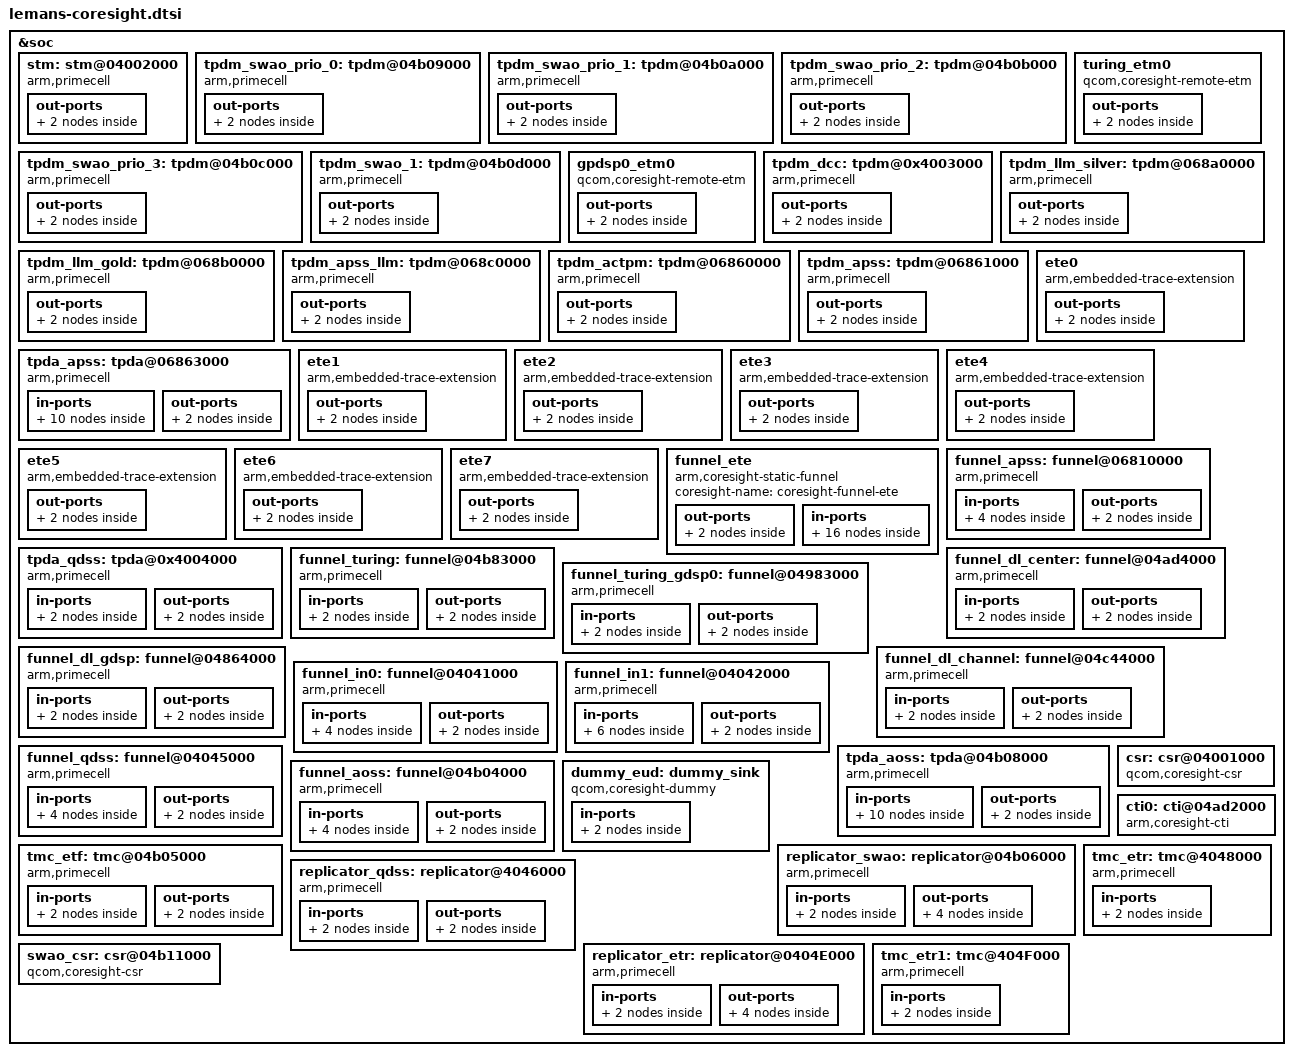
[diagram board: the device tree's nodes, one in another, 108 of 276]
&soc {
	stm: stm@04002000 {
		compatible = "arm,primecell";
		arm,primecell-periphid = <0x000bb962>;
		reg = <0x04002000 0x1000>,
			<0x16280000 0x180000>;
		reg-names = "stm-base", "stm-stimulus-base";

		atid = <16>;
		coresight-name = "coresight-stm";

		clocks = <&aoss_qmp QDSS_CLK>;
		clock-names = "apb_pclk";

		out-ports {
			port {
				stm_out_funnel_in0: endpoint {
					remote-endpoint =
					<&funnel_in0_in_stm>;
				};
			};
		};
	};

	tpdm_swao_prio_0: tpdm@04b09000 {
		compatible = "arm,primecell";
		arm,primecell-periphid = <0x000bb968>;
		reg = <0x04b09000 0x1000>;
		reg-names = "tpdm-base";

		atid = <71>;
		coresight-name = "coresight-tpdm-swao-prio-0";

		clocks = <&aoss_qmp>;
		clock-names = "apb_pclk";

		out-ports {
			port {
				tpdm_swao_prio_0_out_tpda_aoss_0: endpoint {
					remote-endpoint =
					<&tpda_aoss_0_in_tpdm_swao_prio_0>;
				};
			};
		};
	};

	tpdm_swao_prio_1: tpdm@04b0a000 {
		compatible = "arm,primecell";
		arm,primecell-periphid = <0x000bb968>;
		reg = <0x04b0a000 0x1000>;
		reg-names = "tpdm-base";

		atid = <71>;
		coresight-name = "coresight-tpdm-swao-prio-1";

		clocks = <&aoss_qmp>;
		clock-names = "apb_pclk";

		out-ports {
			port {
				tpdm_swao_prio_1_out_tpda_aoss_1: endpoint {
					remote-endpoint =
					<&tpda_aoss_1_in_tpdm_swao_prio_1>;
				};
			};
		};
	};

	tpdm_swao_prio_2: tpdm@04b0b000 {
		compatible = "arm,primecell";
		arm,primecell-periphid = <0x000bb968>;
		reg = <0x04b0b000 0x1000>;
		reg-names = "tpdm-base";

		atid = <71>;
		coresight-name = "coresight-tpdm-swao-prio-2";

		clocks = <&aoss_qmp>;
		clock-names = "apb_pclk";

		out-ports {
			port {
				tpdm_swao_prio_2_out_tpda_aoss_2: endpoint {
					remote-endpoint =
					 <&tpda_aoss_2_in_tpdm_swao_prio_2>;
				};
			};
		};
	};

	tpdm_swao_prio_3: tpdm@04b0c000 {
		compatible = "arm,primecell";
		arm,primecell-periphid = <0x000bb968>;
		reg = <0x04b0c000 0x1000>;
		reg-names = "tpdm-base";

		atid = <71>;
		coresight-name = "coresight-tpdm-swao-prio-3";

		clocks = <&aoss_qmp>;
		clock-names = "apb_pclk";

		out-ports {
			port {
				tpdm_swao_prio_3_out_tpda_aoss_3: endpoint {
					remote-endpoint =
					 <&tpda_aoss_3_in_tpdm_swao_prio_3>;
				};
			};
		};
	};

	tpdm_swao_1: tpdm@04b0d000 {
		compatible = "arm,primecell";
		arm,primecell-periphid = <0x000bb968>;
		reg = <0x04b0d000 0x1000>;
		reg-names = "tpdm-base";

		atid = <71>;
		coresight-name = "coresight-tpdm-swao-1";

		clocks = <&aoss_qmp>;
		clock-names = "apb_pclk";

		out-ports {
			port {
				tpdm_swao_out_tpda_aoss_4: endpoint {
					remote-endpoint =
					<&tpda_aoss_4_in_tpdm_swao>;
				};
			};
		};
	};

	turing_etm0: turing_etm0 {
		compatible = "qcom,coresight-remote-etm";
		coresight-name = "coresight-turing-etm0";
		qcom,inst-id = <13>;
		atid = <38 39>;

		out-ports {
			port {
				turing_etm0_out_funnel_turing_4: endpoint {
					remote-endpoint =
					<&funnel_turing_4_in_turing_etm0>;
				};
			};
		};
	};

	gpdsp0_etm0: gpdsp0_etm0 {
		compatible = "qcom,coresight-remote-etm";

		coresight-name = "coresight-gpdsp-etm0";
		qcom,inst-id = <13>;

		atid = <51 52>;

		out-ports {
			port {
				gpdsp0_etm0_out_funnel_turing_gdsp0_2: endpoint {
					remote-endpoint =
					<&funnel_turing_gdsp0_2_in_gpdsp0_etm0>;
				};
			};
		};
	};

	tpdm_dcc: tpdm@0x4003000 {
		compatible = "arm,primecell";
		arm,primecell-periphid = <0x000bb968>;
		reg = <0x4003000 0x1000>;
		reg-names = "tpdm-base";

		atid = <65>;
		coresight-name = "coresight-tpdm-dcc";

		clocks = <&aoss_qmp>;
		clock-names = "apb_pclk";
		qcom,hw-enable-check;

		out-ports {
			port {
				tpdm_dcc_out_tpda_qdss_0: endpoint {
					remote-endpoint =
					<&tpda_qdss_0_in_tpdm_dcc>;
				};
			};
		};
	};

	tpdm_llm_silver: tpdm@068a0000 {
		compatible = "arm,primecell";
		arm,primecell-periphid = <0x000bb968>;
		reg = <0x068a0000 0x1000>;
		reg-names = "tpdm-base";

		atid = <66>;
		coresight-name = "coresight-tpdm-llm-silver";

		clocks = <&aoss_qmp QDSS_CLK>;
		clock-names = "apb_pclk";

		out-ports {
			port {
				tpdm_llm_silver_out_tpda_apss_0: endpoint {
					remote-endpoint =
					<&tpda_apss_0_in_tpdm_llm_silver>;
				};
			};
		};
	};

	tpdm_llm_gold: tpdm@068b0000 {
		compatible = "arm,primecell";
		arm,primecell-periphid = <0x000bb968>;
		reg = <0x068b0000 0x1000>;
		reg-names = "tpdm-base";

		atid = <66>;
		coresight-name = "coresight-tpdm-llm-gold";

		clocks = <&aoss_qmp QDSS_CLK>;
		clock-names = "apb_pclk";

		out-ports {
			port {
				tpdm_llm_gold_out_tpda_apss_1: endpoint {
					remote-endpoint =
					<&tpda_apss_1_in_tpdm_llm_gold>;
				};
			};
		};
	};

	tpdm_apss_llm: tpdm@068c0000 {
		compatible = "arm,primecell";
		arm,primecell-periphid = <0x000bb968>;
		reg = <0x068c0000 0x1000>;
		reg-names = "tpdm-base";

		atid = <66>;
		coresight-name = "coresight-tpdm-apss-llm";

		clocks = <&aoss_qmp QDSS_CLK>;
		clock-names = "apb_pclk";

		out-ports {
			port {
				tpdm_apss_llm_out_tpda_apss_2: endpoint {
					remote-endpoint =
					<&tpda_apss_2_in_tpdm_apss_llm>;
				};
			};
		};
	};

	tpdm_actpm: tpdm@06860000 {
		compatible = "arm,primecell";
		arm,primecell-periphid = <0x000bb968>;
		reg = <0x06860000 0x1000>;
		reg-names = "tpdm-base";

		atid = <66>;
		coresight-name = "coresight-tpdm-actpm";

		clocks = <&aoss_qmp QDSS_CLK>;
		clock-names = "apb_pclk";

		out-ports {
			port {
				tpdm_apss0_out_tpda_apss_3: endpoint {
					remote-endpoint =
					<&tpda_apss_3_in_tpdm_apss0>;
				};
			};
		};
	};

	tpdm_apss: tpdm@06861000 {
		compatible = "arm,primecell";
		arm,primecell-periphid = <0x000bb968>;
		reg = <0x06861000 0x1000>;
		reg-names = "tpdm-base";

		atid = <66>;
		coresight-name = "coresight-tpdm-apss";

		clocks = <&aoss_qmp QDSS_CLK>;
		clock-names = "apb_pclk";

		out-ports {
			port {
				tpdm_apps1_out_tpda_apss_4: endpoint {
					remote-endpoint =
					<&tpda_apss_4_in_tpdm_apps1>;
				};
			};
		};
	};

	tpda_apss: tpda@06863000 {
		compatible = "arm,primecell";
		arm,primecell-periphid = <0x000bb969>;

		reg = <0x06863000 0x1000>;
		reg-names = "tpda-base";

		qcom,tpda-atid = <66>;

		qcom,dsb-elem-size = <2 32>,
					<4 32>;
		qcom,cmb-elem-size = <0 32>,
				     <1 32>,
				     <3 64>;

		coresight-name = "coresight-tpda-apss";

		clocks = <&aoss_qmp QDSS_CLK>;
		clock-names = "apb_pclk";

		in-ports {

			#address-cells = <1>;
			#size-cells = <0>;

			port@0 {
				reg = <0>;
				tpda_apss_0_in_tpdm_llm_silver: endpoint {
					remote-endpoint =
					<&tpdm_llm_silver_out_tpda_apss_0>;
				};
			};

			port@1 {
				reg = <1>;
				tpda_apss_1_in_tpdm_llm_gold: endpoint {
					remote-endpoint =
					<&tpdm_llm_gold_out_tpda_apss_1>;
				};
			};

			port@3 {
				reg = <3>;
				tpda_apss_3_in_tpdm_apss0: endpoint {
					remote-endpoint =
					<&tpdm_apss0_out_tpda_apss_3>;
				};
			};

			port@2 {
				reg = <2>;
				tpda_apss_2_in_tpdm_apss_llm: endpoint {
					remote-endpoint =
					<&tpdm_apss_llm_out_tpda_apss_2>;
				};
			};

			port@4 {
				reg = <4>;
				tpda_apss_4_in_tpdm_apps1: endpoint {
					remote-endpoint =
					<&tpdm_apps1_out_tpda_apss_4>;
				};
			};

		};

		out-ports {

			port {
				tpda_apss_out_funnel_apss: endpoint {
					remote-endpoint =
					<&funnel_apss_in_tpda_apss>;
				};
			};

		};
	};

	ete0 {
		compatible = "arm,embedded-trace-extension";
		cpu = <&CPU0>;

		coresight-name = "coresight-ete0";
		qcom,skip-power-up;
		atid = <1>;
		out-ports {
			port {
				ete0_out_funnel_ete: endpoint {
				remote-endpoint = <&funnel_ete_in_ete0>;
				};
			};
		};
	};

	ete1 {
		compatible = "arm,embedded-trace-extension";
		cpu = <&CPU1>;

		coresight-name = "coresight-ete1";
		qcom,skip-power-up;
		atid = <2>;
		out-ports {
			port {
				ete1_out_funnel_ete: endpoint {
				remote-endpoint = <&funnel_ete_in_ete1>;
				};
			};
		};
	};

	ete2 {
		compatible = "arm,embedded-trace-extension";
		cpu = <&CPU2>;

		coresight-name = "coresight-ete2";
		qcom,skip-power-up;
		atid = <3>;
		out-ports {
			port {
				ete2_out_funnel_ete: endpoint {
				remote-endpoint = <&funnel_ete_in_ete2>;
				};
			};
		};
	};

	ete3 {
		compatible = "arm,embedded-trace-extension";
		cpu = <&CPU3>;

		coresight-name = "coresight-ete3";
		qcom,skip-power-up;
		atid = <4>;
		out-ports {
			port {
				ete3_out_funnel_ete: endpoint {
				remote-endpoint = <&funnel_ete_in_ete3>;
				};
			};
		};
	};

	ete4 {
		compatible = "arm,embedded-trace-extension";
		cpu = <&CPU4>;

		coresight-name = "coresight-ete4";
		qcom,skip-power-up;
		atid = <5>;
		out-ports {
			port {
				ete4_out_funnel_ete: endpoint {
				remote-endpoint = <&funnel_ete_in_ete4>;
				};
			};
		};
	};

	ete5 {
		compatible = "arm,embedded-trace-extension";
		cpu = <&CPU5>;

		coresight-name = "coresight-ete5";
		qcom,skip-power-up;
		atid = <6>;
		out-ports {
			port {
				ete5_out_funnel_ete: endpoint {
				remote-endpoint = <&funnel_ete_in_ete5>;
				};
			};
		};
	};

	ete6 {
		compatible = "arm,embedded-trace-extension";
		cpu = <&CPU6>;

		coresight-name = "coresight-ete6";
		qcom,skip-power-up;
		atid = <7>;
		out-ports {
			port {
				ete6_out_funnel_ete: endpoint {
				remote-endpoint = <&funnel_ete_in_ete6>;
				};
			};
		};
	};

	ete7 {
		compatible = "arm,embedded-trace-extension";
		cpu = <&CPU7>;

		coresight-name = "coresight-ete7";
		qcom,skip-power-up;
		atid = <8>;
		out-ports {
			port {
				ete7_out_funnel_ete: endpoint {
				remote-endpoint = <&funnel_ete_in_ete7>;
				};
			};
		};
	};

	funnel_ete {
		compatible = "arm,coresight-static-funnel";
		coresight-name = "coresight-funnel-ete";

		out-ports {
			port {
				funnel_ete_out_funnel_apss: endpoint {
					remote-endpoint =
					<&funnel_apss_in_funnel_ete>;
				};
			};
		};

		in-ports {
			#address-cells = <1>;
			#size-cells = <0>;

			port@0 {
				reg = <0>;
				funnel_ete_in_ete0: endpoint {
					remote-endpoint =
					<&ete0_out_funnel_ete>;
				};
			};

			port@1 {
				reg = <1>;
				funnel_ete_in_ete1: endpoint {
				remote-endpoint =
					<&ete1_out_funnel_ete>;
				};
			};

			port@2 {
				reg = <2>;
				funnel_ete_in_ete2: endpoint {
				remote-endpoint =
					<&ete2_out_funnel_ete>;
				};
			};

			port@3 {
				reg = <3>;
				funnel_ete_in_ete3: endpoint {
				remote-endpoint =
					<&ete3_out_funnel_ete>;
				};
			};

			port@4 {
				reg = <4>;
				funnel_ete_in_ete4: endpoint {
				remote-endpoint =
					<&ete4_out_funnel_ete>;
				};
			};

			port@5 {
				reg = <5>;
				funnel_ete_in_ete5: endpoint {
					remote-endpoint =
					<&ete5_out_funnel_ete>;
				};
			};

			port@6 {
				reg = <6>;
				funnel_ete_in_ete6: endpoint {
					remote-endpoint =
					<&ete6_out_funnel_ete>;
				};
			};

			port@7 {
				reg = <7>;
				funnel_ete_in_ete7: endpoint {
					remote-endpoint =
					<&ete7_out_funnel_ete>;
				};
			};
		};
	};

	funnel_apss: funnel@06810000 {
		compatible = "arm,primecell";
		arm,primecell-periphid = <0x000bb908>;

		reg = <0x06810000 0x1000>;
		reg-names = "funnel-base";

		coresight-name = "coresight-funnel-apss";

		clocks = <&aoss_qmp QDSS_CLK>;
		clock-names = "apb_pclk";

		in-ports {
			#address-cells = <1>;
			#size-cells = <0>;


			port@0 {
				reg = <0>;
				funnel_apss_in_funnel_ete: endpoint {
					remote-endpoint =
					<&funnel_ete_out_funnel_apss>;
				};
			};


			port@3 {
				reg = <3>;
				funnel_apss_in_tpda_apss: endpoint {
					remote-endpoint =
					<&tpda_apss_out_funnel_apss>;
				};
			};

		};

		out-ports {
			port {
				funnel_apss_out_funnel_in1: endpoint {
					remote-endpoint =
					<&funnel_in1_in_funnel_apss>;
				};
			};

		};
	};

	tpda_qdss: tpda@0x4004000 {
		compatible = "arm,primecell";
		arm,primecell-periphid = <0x000bb969>;

		reg = <0x4004000 0x1000>;
		reg-names = "tpda-base";

		qcom,tpda-atid = <65>;
		coresight-name = "coresight-tpda-qdss";

		clocks = <&aoss_qmp>;
		clock-names = "apb_pclk";

		in-ports {

			#address-cells = <1>;
			#size-cells = <0>;

			port@0 {
				reg = <0>;
				tpda_qdss_0_in_tpdm_dcc: endpoint {
					remote-endpoint =
					<&tpdm_dcc_out_tpda_qdss_0>;
				};
			};
		};

		out-ports {

			port {
				tpda_qdss_out_funnel_in0: endpoint {
					remote-endpoint =
					<&funnel_in0_in_tpda_qdss>;
				};
			};
		};
	};

	funnel_turing: funnel@04b83000 {
		compatible = "arm,primecell";
		arm,primecell-periphid = <0x000bb908>;

		reg = <0x04b83000 0x1000>;
		reg-names = "funnel-base";

		coresight-name = "coresight-funnel-turing";

		clocks = <&aoss_qmp>;
		clock-names = "apb_pclk";

		in-ports {
			#address-cells = <1>;
			#size-cells = <0>;

			port@4 {
				reg = <4>;
				funnel_turing_4_in_turing_etm0: endpoint {
					remote-endpoint =
					<&turing_etm0_out_funnel_turing_4>;
				};
			};

		};

		out-ports {
			#address-cells = <1>;
			#size-cells = <0>;

			port {
				funnel_turing_out_funnel_dl_center_6: endpoint {
					remote-endpoint =
					<&funnel_dl_center_6_in_funnel_turing>;
				};
			};

		};
	};

	funnel_dl_center: funnel@04ad4000 {
		compatible = "arm,primecell";
		arm,primecell-periphid = <0x000bb908>;

		reg = <0x04ad4000 0x1000>;
		reg-names = "funnel-base";

		coresight-name = "coresight-funnel-dl_center";

		clocks = <&aoss_qmp>;
		clock-names = "apb_pclk";

		in-ports {
			#address-cells = <1>;
			#size-cells = <0>;

			port@6 {
				reg = <6>;
				funnel_dl_center_6_in_funnel_turing: endpoint {
					remote-endpoint =
					<&funnel_turing_out_funnel_dl_center_6>;
				};
			};

		};

		out-ports {
			port {
				funnel_dl_center_out_funnel_in1_5: endpoint {
					remote-endpoint =
					<&funnel_in1_5_in_funnel_dl_center>;
				};
			};

		};
	};

	funnel_turing_gdsp0: funnel@04983000 {
		compatible = "arm,primecell";
		arm,primecell-periphid = <0x000bb908>;

		reg = <0x04984000 0x1000>,
			<0x04983000 0x1000>;
		reg-names = "funnel-base-dummy", "funnel-base-real";

		coresight-name = "coresight-funnel-turing_gdsp0";

		qcom,duplicate-funnel;
		clocks = <&aoss_qmp>;
		clock-names = "apb_pclk";

		in-ports {
			#address-cells = <1>;
			#size-cells = <0>;
			port@2 {
				reg = <2>;
				funnel_turing_gdsp0_2_in_gpdsp0_etm0: endpoint {
					remote-endpoint =
					<&gpdsp0_etm0_out_funnel_turing_gdsp0_2>;
				};
			};
		};

		out-ports {
			port {
				funnel_turing_gdsp0_out_funnel_dl_gdsp_3: endpoint {
					remote-endpoint =
					<&funnel_dl_gdsp_3_in_funnel_turing_gdsp0>;
				};
			};

		};
	};

	funnel_dl_gdsp: funnel@04864000 {
		compatible = "arm,primecell";
		arm,primecell-periphid = <0x000bb908>;

		reg = <0x04864000 0x1000>;
		reg-names = "funnel-base";

		coresight-name = "coresight-funnel-dl_gdsp";

		clocks = <&aoss_qmp>;
		clock-names = "apb_pclk";

		in-ports {
			#address-cells = <1>;
			#size-cells = <0>;

			port@3 {
				reg = <3>;
				funnel_dl_gdsp_3_in_funnel_turing_gdsp0: endpoint {
					remote-endpoint =
					<&funnel_turing_gdsp0_out_funnel_dl_gdsp_3>;
				};
			};
		};

		out-ports {
			port {
				funnel_dl_gdsp_out_funnel_dl_channel_5: endpoint {
					remote-endpoint =
					<&funnel_dl_channel_5_in_funnel_dl_gdsp>;
				};
			};
		};
	};

	funnel_dl_channel: funnel@04c44000 {
		compatible = "arm,primecell";
		arm,primecell-periphid = <0x000bb908>;

		reg = <0x04c44000 0x1000>;
		reg-names = "funnel-base";

		coresight-name = "coresight-funnel-dl_channel";

		clocks = <&aoss_qmp>;
		clock-names = "apb_pclk";

		in-ports {
			#address-cells = <1>;
			#size-cells = <0>;

			port@5 {
				reg = <5>;
				funnel_dl_channel_5_in_funnel_dl_gdsp: endpoint {
					remote-endpoint =
					<&funnel_dl_gdsp_out_funnel_dl_channel_5>;
				};
			};
		};

		out-ports {
			port {
				funnel_dl_channel_out_funnel_in1_6: endpoint {
					remote-endpoint =
					<&funnel_in1_6_in_funnel_dl_channel>;
				};
			};
		};
	};

	funnel_in0: funnel@04041000 {
		compatible = "arm,primecell";
		arm,primecell-periphid = <0x000bb908>;

		reg = <0x04041000 0x1000>;
		reg-names = "funnel-base";

		coresight-name = "coresight-funnel-in0";

		clocks = <&aoss_qmp QDSS_CLK>;
		clock-names = "apb_pclk";

		in-ports {
			#address-cells = <1>;
			#size-cells = <0>;

			port@7 {
				reg = <7>;
				funnel_in0_in_stm: endpoint {
					remote-endpoint =
					<&stm_out_funnel_in0>;
				};
			};

			port@6 {
				reg = <6>;
				funnel_in0_in_tpda_qdss: endpoint {
					remote-endpoint =
					<&tpda_qdss_out_funnel_in0>;
				};
			};

		};

		out-ports {
			port {
				funnel_in0_out_funnel_qdss: endpoint {
					remote-endpoint =
					<&funnel_qdss_in_funnel_in0>;
				};
			};

		};
	};

	funnel_in1: funnel@04042000 {
		compatible = "arm,primecell";
		arm,primecell-periphid = <0x000bb908>;

		reg = <0x04042000 0x1000>;
		reg-names = "funnel-base";

		coresight-name = "coresight-funnel-in1";

		clocks = <&aoss_qmp QDSS_CLK>;
		clock-names = "apb_pclk";

		in-ports {
			#address-cells = <1>;
			#size-cells = <0>;

			port@4 {
				reg = <4>;
				funnel_in1_in_funnel_apss: endpoint {
					remote-endpoint =
					<&funnel_apss_out_funnel_in1>;
				};
			};

			port@5 {
				reg = <5>;
				funnel_in1_5_in_funnel_dl_center: endpoint {
					remote-endpoint =
					<&funnel_dl_center_out_funnel_in1_5>;
				};
			};

			port@6 {
				reg = <6>;
				funnel_in1_6_in_funnel_dl_channel: endpoint {
					remote-endpoint =
					<&funnel_dl_channel_out_funnel_in1_6>;
				};
			};

		};

		out-ports {
			port {
				funnel_in1_out_funnel_qdss: endpoint {
					remote-endpoint =
					<&funnel_qdss_in_funnel_in1>;
				};
			};

		};
	};

	funnel_qdss: funnel@04045000 {
		compatible = "arm,primecell";
		arm,primecell-periphid = <0x000bb908>;

		reg = <0x04045000 0x1000>;
		reg-names = "funnel-base";

		coresight-name = "coresight-funnel-qdss";

		clocks = <&aoss_qmp QDSS_CLK>;
		clock-names = "apb_pclk";

		in-ports {
			#address-cells = <1>;
			#size-cells = <0>;

			port@1 {
				reg = <1>;
				funnel_qdss_in_funnel_in1: endpoint {
					remote-endpoint =
					<&funnel_in1_out_funnel_qdss>;
				};
			};

			port@0 {
				reg = <0>;
				funnel_qdss_in_funnel_in0: endpoint {
					remote-endpoint =
					<&funnel_in0_out_funnel_qdss>;
				};
			};

		};

		out-ports {
			port {
				funnel_qdss_out_funnel_aoss: endpoint {
					remote-endpoint =
					<&funnel_aoss_in_funnel_qdss>;
				};
			};

		};
	};

	tpda_aoss: tpda@04b08000 {
		compatible = "arm,primecell";
		arm,primecell-periphid = <0x000bb969>;

		reg = <0x04b08000 0x1000>;
		reg-names = "tpda-base";

		coresight-name = "coresight-tpda-aoss";

		qcom,tpda-atid = <71>;

		qcom,cmb-elem-size = <0 64>,
							<1 64>,
							<2 64>,
							<3 64>;

		qcom,dsb-elem-size = <4 32>;

		clocks = <&aoss_qmp>;
		clock-names = "apb_pclk";

		in-ports {
			#address-cells = <1>;
			#size-cells = <0>;

			port@0 {
				reg = <0>;
				tpda_aoss_0_in_tpdm_swao_prio_0: endpoint {
					remote-endpoint =
					<&tpdm_swao_prio_0_out_tpda_aoss_0>;
				};
			};

			port@1 {
				reg = <1>;
				tpda_aoss_1_in_tpdm_swao_prio_1: endpoint {
					remote-endpoint =
					<&tpdm_swao_prio_1_out_tpda_aoss_1>;
				};
			};

			port@2 {
				reg = <2>;
				tpda_aoss_2_in_tpdm_swao_prio_2: endpoint {
					remote-endpoint =
					<&tpdm_swao_prio_2_out_tpda_aoss_2>;
				};
			};

			port@3 {
				reg = <3>;
				tpda_aoss_3_in_tpdm_swao_prio_3: endpoint {
					remote-endpoint =
					<&tpdm_swao_prio_3_out_tpda_aoss_3>;
				};
			};

			port@4 {
				reg = <4>;
				tpda_aoss_4_in_tpdm_swao: endpoint {
					remote-endpoint =
					<&tpdm_swao_out_tpda_aoss_4>;
				};
			};

		};

		out-ports {

			port {
				tpda_aoss_out_funnel_aoss: endpoint {
					remote-endpoint =
					<&funnel_aoss_in_tpda_aoss>;
				};
			};

		};
	};

	funnel_aoss: funnel@04b04000 {
		compatible = "arm,primecell";
		arm,primecell-periphid = <0x000bb908>;

		reg = <0x04b04000 0x1000>;
		reg-names = "funnel-base";

		coresight-name = "coresight-funnel-aoss";

		clocks = <&aoss_qmp QDSS_CLK>;
		clock-names = "apb_pclk";

		in-ports {
			#address-cells = <1>;
			#size-cells = <0>;

			port@7 {
				reg = <7>;
				funnel_aoss_in_funnel_qdss: endpoint {
					remote-endpoint =
					<&funnel_qdss_out_funnel_aoss>;
				};
			};

			port@6 {
				reg = <6>;
				funnel_aoss_in_tpda_aoss: endpoint {
					remote-endpoint =
					<&tpda_aoss_out_funnel_aoss>;
				};
			};
		};

		out-ports {
			port {
				funnel_aoss_out_tmc_etf: endpoint {
					remote-endpoint =
					<&tmc_etf_in_funnel_aoss>;
				};
			};
		};

	};

	dummy_eud: dummy_sink {
		compatible = "qcom,coresight-dummy";

		coresight-name = "coresight-eud";

		qcom,dummy-sink;
		in-ports {
			port {
				eud_in_replicator_swao: endpoint {
					remote-endpoint =
					<&replicator_swao_out_eud>;
				};
			};
		};
	};

	tmc_etf: tmc@04b05000 {
		compatible = "arm,primecell";
		arm,primecell-periphid = <0x000bb961>;
		reg = <0x04b05000 0x1000>;
		reg-names = "tmc-base";

		coresight-name = "coresight-tmc-etf";
		cti-reset-trig-num = <0>;
		cti-flush-trig-num = <1>;
		coresight-csr = <&csr>;
		arm,default-sink;

		clocks = <&aoss_qmp QDSS_CLK>;
		clock-names = "apb_pclk";

		in-ports {
			port {
				tmc_etf_in_funnel_aoss: endpoint {
					remote-endpoint =
					<&funnel_aoss_out_tmc_etf>;
				};
			};
		};

		out-ports {
			port {
				tmc_etf_out_replicator_swao: endpoint {
					remote-endpoint =
					<&replicator_swao_in_tmc_etf>;
				};
			};
		};
	};


	replicator_swao: replicator@04b06000 {
		compatible = "arm,primecell";
		arm,primecell-periphid = <0x000bb909>;
		reg = <0x04b06000 0x1000>;
		reg-names = "replicator-base";

		coresight-name = "coresight-replicator_swao";

		clocks = <&aoss_qmp QDSS_CLK>;
		clock-names = "apb_pclk";

		in-ports {
			port {
				replicator_swao_in_tmc_etf: endpoint {
					remote-endpoint = <&tmc_etf_out_replicator_swao>;
				};
			};
		};

		out-ports {
			#address-cells = <1>;
			#size-cells = <0>;

			port@0 {
				reg = <0>;
				replicator_swao_out_replicator_qdss: endpoint {
					remote-endpoint =
					<&replicator_qdss_in_replicator_swao>;
				};
			};

			port@1 {
				reg = <1>;
				replicator_swao_out_eud: endpoint {
					remote-endpoint =
					  <&eud_in_replicator_swao>;
				};
			};
		};
	};

	replicator_qdss: replicator@4046000 {
		compatible = "arm,primecell";
		arm,primecell-periphid = <0x000bb909>;
		reg = <0x04046000 0x1000>;
		reg-names = "replicator-base";

		coresight-name = "coresight-replicator_qdss";

		clocks = <&aoss_qmp QDSS_CLK>;
		clock-names = "apb_pclk";

		in-ports {
			port {
				replicator_qdss_in_replicator_swao: endpoint {
					remote-endpoint =
					<&replicator_swao_out_replicator_qdss>;
				};
			};
		};

		out-ports {
			#address-cells = <1>;
			#size-cells = <0>;

			port@0 {
				reg = <0>;
				replicator_qdss_out_replicator_etr: endpoint {
					remote-endpoint =
					<&replicator_etr_in_replicator_qdss>;
				};
			};
		};
	};

	replicator_etr: replicator@0404E000 {
		compatible = "arm,primecell";
		arm,primecell-periphid = <0x000bb909>;
		reg = <0x0404E000 0x1000>;
		reg-names = "replicator-base";

		coresight-name = "coresight-replicator_etr";

		clocks = <&aoss_qmp QDSS_CLK>;
		clock-names = "apb_pclk";

		in-ports {
			port {
				replicator_etr_in_replicator_qdss: endpoint {
					remote-endpoint =
					<&replicator_qdss_out_replicator_etr>;
				};
			};
		};

		out-ports {
			#address-cells = <1>;
			#size-cells = <0>;

			port@0 {
				reg = <0>;
				replicator_etr_out_tmc_etr: endpoint {
					remote-endpoint =
					<&tmc_etr_in_replicator_etr>;
				};
			};

			port@1 {
				reg = <1>;
				replicator_etr_out_tmc_etr1: endpoint {
					remote-endpoint =
					<&tmc_etr1_in_replicator_etr>;
				};
			};
		};
	};

	csr: csr@04001000 {
		compatible = "qcom,coresight-csr";
		reg = <0x04001000 0x1000>;
		reg-names = "csr-base";

		coresight-name = "coresight-csr";
		qcom,hwctrl-set-support;
		qcom,set-byte-cntr-support;

		qcom,blk-size = <1>;
	};

	cti0: cti@04ad2000 {
		compatible = "arm,coresight-cti", "arm,primecell";
		reg = <0x04ad2000 0x1000>;
		reg-names = "cti-base";
		arm,primecell-periphid = <0x000bb922>;
		coresight-name = "coresight-cti-cti0";
		qcom,extended_cti;
		clocks = <&aoss_qmp>;
		clock-names = "apb_pclk";
	};

	swao_csr: csr@04b11000 {
		compatible = "qcom,coresight-csr";
		reg = <0x04B11000 0x1000>,
		      <0x04B110f8 0x50>;
		reg-names = "csr-base", "msr-base";

		coresight-name = "coresight-swao-csr";
		qcom,timestamp-support;
		qcom,msr-support;

		clocks = <&aoss_qmp QDSS_CLK>;
		clock-names = "apb_pclk";

		qcom,blk-size = <1>;
	};

	tmc_etr: tmc@4048000 {
		compatible = "arm,primecell";
		arm,primecell-periphid = <0x000bb961>;
		reg = <0x4048000 0x1000>,
			<0x4064000 0x16000>;
		reg-names = "tmc-base", "bam-base";

		qcom,iommu-dma = "bypass";
		iommus = <&apps_smmu 0x04e0 0x40>,
			<&apps_smmu 0x04a0 0x0>;

		qcom,iommu-dma-addr-pool = <0x0 0xffc00000>;

		coresight-name = "coresight-tmc-etr";

		qcom,mem_support;
		qcom,sw-usb;
		dma-coherent;
		coresight-csr = <&csr>;
		csr-atid-offset = <0xf8>;
		csr-irqctrl-offset = <0x6c>;
		byte-cntr-name = "byte-cntr";
		byte-cntr-class-name = "coresight-tmc-etr-stream";

		interrupts = <GIC_SPI 270 IRQ_TYPE_EDGE_RISING>;
		interrupt-names = "byte-cntr-irq";

		arm,scatter-gather;
		clocks = <&aoss_qmp QDSS_CLK>;
		clock-names = "apb_pclk";
		in-ports {
			port {
				tmc_etr_in_replicator_etr: endpoint {
					remote-endpoint =
					<&replicator_etr_out_tmc_etr>;
				};
			};
		};
	};

	tmc_etr1: tmc@404F000 {
		compatible = "arm,primecell";
		arm,primecell-periphid = <0x000bb961>;
		reg = <0x0404F000 0x1000>;
		reg-names = "tmc-base";

		#address-cells = <1>;
		#size-cells = <1>;
		ranges;

		qcom,mem_support;
		qcom,sw-usb;
		dma-coherent;
		arm,buffer-size = <0x400000>;
		coresight-name = "coresight-tmc-etr1";
		coresight-ctis = <&cti0 &cti0>;
		cti-reset-trig-num = <0>;
		cti-flush-trig-num = <3>;
		coresight-csr = <&csr>;
		csr-atid-offset = <0x108>;
		byte-cntr-name = "byte-cntr1";
		byte-cntr-class-name = "coresight-tmc-etr1-stream";
		clocks = <&aoss_qmp QDSS_CLK>;
		clock-names = "apb_pclk";
		arm,scatter-gather;

		qcom,iommu-dma = "bypass";
		iommus = <&apps_smmu 0x04c0 0x00>,
					<&apps_smmu 0x04E0 0x40>,
					<&apps_smmu 0x04A0 0x40>;
		qcom,iommu-dma-addr-pool = <0x0 0xffc00000>;
		interrupts = <GIC_SPI 262 IRQ_TYPE_EDGE_RISING>;
		interrupt-names = "byte-cntr-irq";

		in-ports {
			port {
				tmc_etr1_in_replicator_etr: endpoint {
					remote-endpoint =
					<&replicator_etr_out_tmc_etr1>;
				};
			};
		};
	};

};
